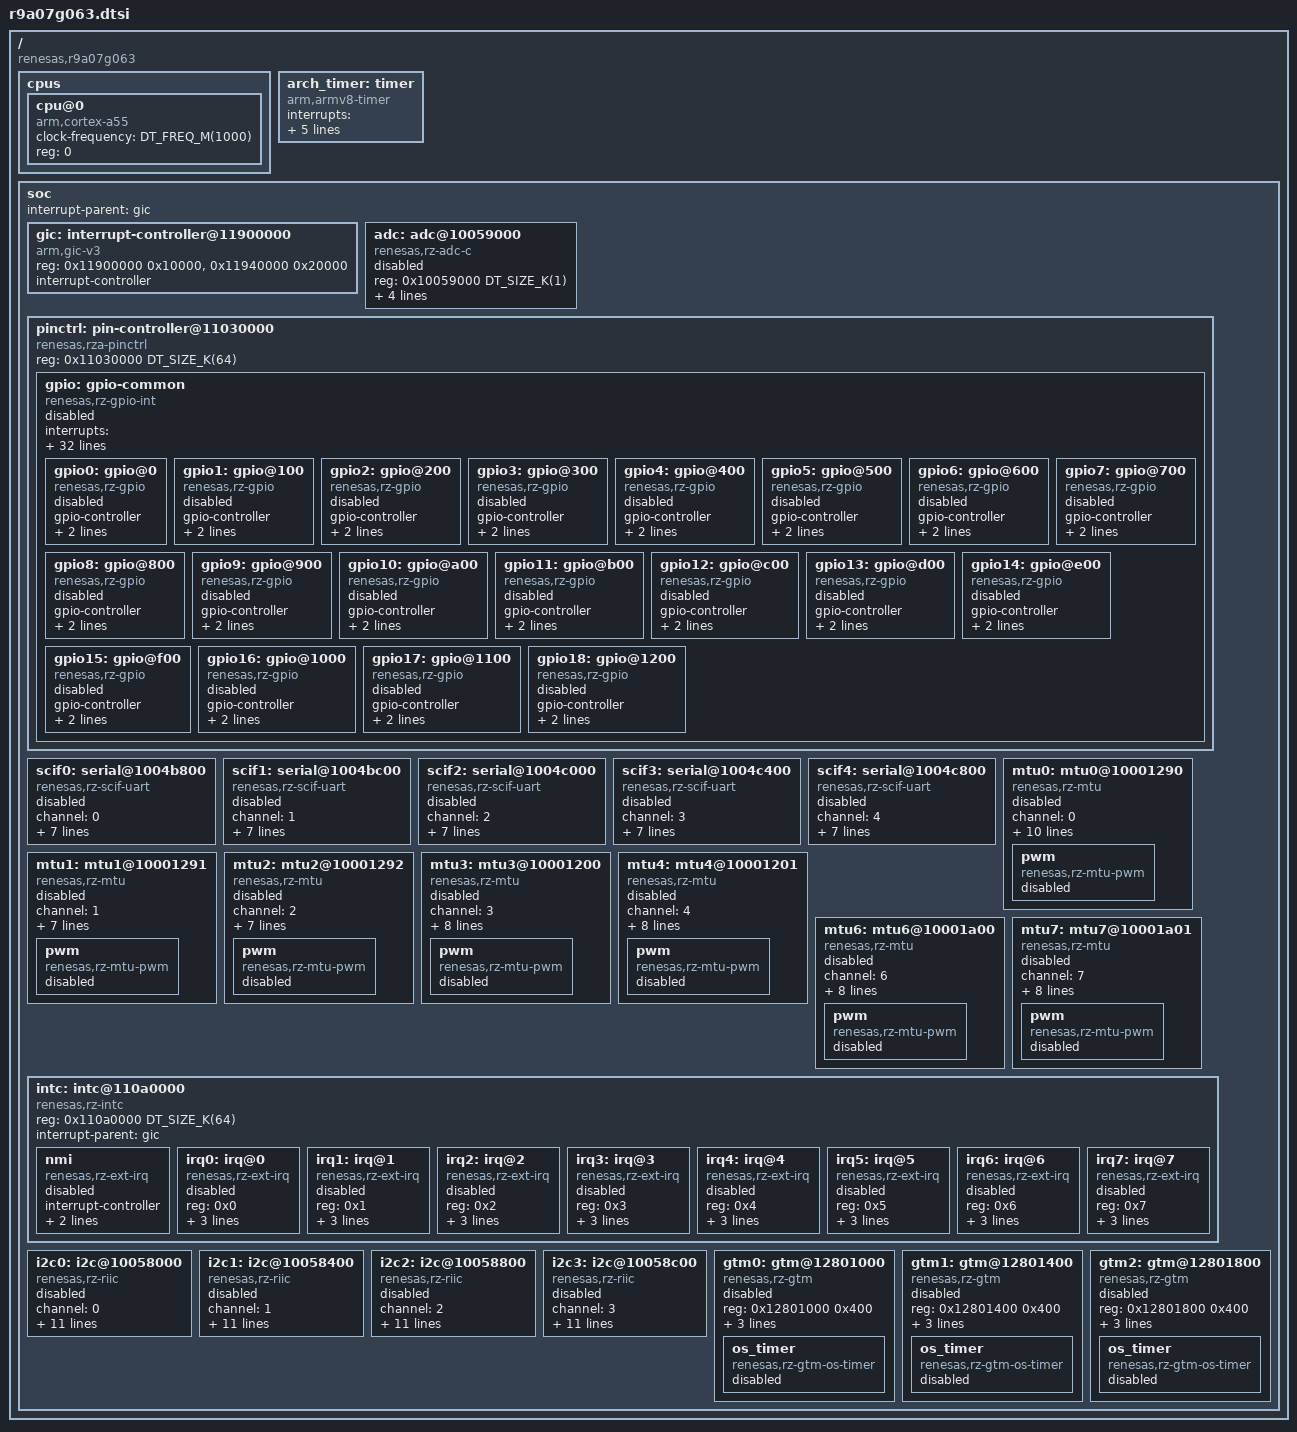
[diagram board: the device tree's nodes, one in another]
/*
 * Copyright (c) 2025 Renesas Electronics Corporation
 *
 * SPDX-License-Identifier: Apache-2.0
 */

#include <mem.h>
#include <freq.h>
#include <arm64/armv8-a.dtsi>
#include <zephyr/dt-bindings/interrupt-controller/arm-gic.h>
#include <zephyr/dt-bindings/gpio/gpio.h>
#include <zephyr/dt-bindings/pwm/renesas_rz_pwm.h>
#include <zephyr/dt-bindings/adc/adc.h>
#include <zephyr/dt-bindings/i2c/i2c.h>

/ {
	compatible = "renesas,r9a07g063";
	#address-cells = <1>;
	#size-cells = <1>;

	cpus {
		#address-cells = <1>;
		#size-cells = <0>;

		cpu@0 {
			device_type = "cpu";
			compatible = "arm,cortex-a55";
			clock-frequency = <DT_FREQ_M(1000)>;
			reg = <0>;
		};
	};

	arch_timer: timer {
		compatible = "arm,armv8-timer";
		interrupts = <GIC_PPI 13 IRQ_TYPE_LEVEL IRQ_DEFAULT_PRIORITY>,
			     <GIC_PPI 14 IRQ_TYPE_LEVEL IRQ_DEFAULT_PRIORITY>,
			     <GIC_PPI 11 IRQ_TYPE_LEVEL IRQ_DEFAULT_PRIORITY>,
			     <GIC_PPI 10 IRQ_TYPE_LEVEL IRQ_DEFAULT_PRIORITY>;
		interrupt-parent = <&gic>;
	};

	soc {
		interrupt-parent = <&gic>;

		gic: interrupt-controller@11900000 {
			compatible = "arm,gic-v3", "arm,gic";
			reg = <0x11900000 0x10000>, /* GICD */
			      <0x11940000 0x20000>; /* GICR */
			interrupt-controller;
			#interrupt-cells = <4>;
			status = "okay";
		};

		adc: adc@10059000 {
			compatible = "renesas,rz-adc-c";
			reg = <0x10059000 DT_SIZE_K(1)>;
			interrupts = <GIC_SPI 347 IRQ_TYPE_EDGE IRQ_DEFAULT_PRIORITY>;
			interrupt-names = "scanend";
			#io-channel-cells = <1>;
			vref-mv = <1800>;
			channel-available-mask = <0x3>;
			status = "disabled";
		};

		pinctrl: pin-controller@11030000 {
			compatible = "renesas,rza-pinctrl";
			reg = <0x11030000 DT_SIZE_K(64)>;
			reg-names = "pinctrl";

			gpio: gpio-common {
				compatible = "renesas,rz-gpio-int";
				interrupts = <GIC_SPI 444 IRQ_TYPE_LEVEL IRQ_DEFAULT_PRIORITY>,
					     <GIC_SPI 445 IRQ_TYPE_LEVEL IRQ_DEFAULT_PRIORITY>,
					     <GIC_SPI 446 IRQ_TYPE_LEVEL IRQ_DEFAULT_PRIORITY>,
					     <GIC_SPI 447 IRQ_TYPE_LEVEL IRQ_DEFAULT_PRIORITY>,
					     <GIC_SPI 448 IRQ_TYPE_LEVEL IRQ_DEFAULT_PRIORITY>,
					     <GIC_SPI 449 IRQ_TYPE_LEVEL IRQ_DEFAULT_PRIORITY>,
					     <GIC_SPI 450 IRQ_TYPE_LEVEL IRQ_DEFAULT_PRIORITY>,
					     <GIC_SPI 451 IRQ_TYPE_LEVEL IRQ_DEFAULT_PRIORITY>,
					     <GIC_SPI 452 IRQ_TYPE_LEVEL IRQ_DEFAULT_PRIORITY>,
					     <GIC_SPI 453 IRQ_TYPE_LEVEL IRQ_DEFAULT_PRIORITY>,
					     <GIC_SPI 454 IRQ_TYPE_LEVEL IRQ_DEFAULT_PRIORITY>,
					     <GIC_SPI 455 IRQ_TYPE_LEVEL IRQ_DEFAULT_PRIORITY>,
					     <GIC_SPI 456 IRQ_TYPE_LEVEL IRQ_DEFAULT_PRIORITY>,
					     <GIC_SPI 457 IRQ_TYPE_LEVEL IRQ_DEFAULT_PRIORITY>,
					     <GIC_SPI 458 IRQ_TYPE_LEVEL IRQ_DEFAULT_PRIORITY>,
					     <GIC_SPI 459 IRQ_TYPE_LEVEL IRQ_DEFAULT_PRIORITY>,
					     <GIC_SPI 460 IRQ_TYPE_LEVEL IRQ_DEFAULT_PRIORITY>,
					     <GIC_SPI 461 IRQ_TYPE_LEVEL IRQ_DEFAULT_PRIORITY>,
					     <GIC_SPI 462 IRQ_TYPE_LEVEL IRQ_DEFAULT_PRIORITY>,
					     <GIC_SPI 463 IRQ_TYPE_LEVEL IRQ_DEFAULT_PRIORITY>,
					     <GIC_SPI 464 IRQ_TYPE_LEVEL IRQ_DEFAULT_PRIORITY>,
					     <GIC_SPI 465 IRQ_TYPE_LEVEL IRQ_DEFAULT_PRIORITY>,
					     <GIC_SPI 466 IRQ_TYPE_LEVEL IRQ_DEFAULT_PRIORITY>,
					     <GIC_SPI 467 IRQ_TYPE_LEVEL IRQ_DEFAULT_PRIORITY>,
					     <GIC_SPI 468 IRQ_TYPE_LEVEL IRQ_DEFAULT_PRIORITY>,
					     <GIC_SPI 469 IRQ_TYPE_LEVEL IRQ_DEFAULT_PRIORITY>,
					     <GIC_SPI 470 IRQ_TYPE_LEVEL IRQ_DEFAULT_PRIORITY>,
					     <GIC_SPI 471 IRQ_TYPE_LEVEL IRQ_DEFAULT_PRIORITY>,
					     <GIC_SPI 472 IRQ_TYPE_LEVEL IRQ_DEFAULT_PRIORITY>,
					     <GIC_SPI 473 IRQ_TYPE_LEVEL IRQ_DEFAULT_PRIORITY>,
					     <GIC_SPI 474 IRQ_TYPE_LEVEL IRQ_DEFAULT_PRIORITY>,
					     <GIC_SPI 475 IRQ_TYPE_LEVEL IRQ_DEFAULT_PRIORITY>;
				#address-cells = <1>;
				#size-cells = <0>;
				status = "disabled";

				gpio0: gpio@0 {
					compatible = "renesas,rz-gpio";
					gpio-controller;
					#gpio-cells = <2>;
					ngpios = <4>;
					reg = <0x0>;
					status = "disabled";
				};

				gpio1: gpio@100 {
					compatible = "renesas,rz-gpio";
					gpio-controller;
					#gpio-cells = <2>;
					ngpios = <5>;
					reg = <0x100>;
					status = "disabled";
				};

				gpio2: gpio@200 {
					compatible = "renesas,rz-gpio";
					gpio-controller;
					#gpio-cells = <2>;
					ngpios = <4>;
					reg = <0x200>;
					status = "disabled";
				};

				gpio3: gpio@300 {
					compatible = "renesas,rz-gpio";
					gpio-controller;
					#gpio-cells = <2>;
					ngpios = <4>;
					reg = <0x300>;
					status = "disabled";
				};

				gpio4: gpio@400 {
					compatible = "renesas,rz-gpio";
					gpio-controller;
					#gpio-cells = <2>;
					ngpios = <6>;
					reg = <0x400>;
					status = "disabled";
				};

				gpio5: gpio@500 {
					compatible = "renesas,rz-gpio";
					gpio-controller;
					#gpio-cells = <2>;
					ngpios = <5>;
					reg = <0x500>;
					status = "disabled";
				};

				gpio6: gpio@600 {
					compatible = "renesas,rz-gpio";
					gpio-controller;
					#gpio-cells = <2>;
					ngpios = <5>;
					reg = <0x600>;
					status = "disabled";
				};

				gpio7: gpio@700 {
					compatible = "renesas,rz-gpio";
					gpio-controller;
					#gpio-cells = <2>;
					ngpios = <5>;
					reg = <0x700>;
					status = "disabled";
				};

				gpio8: gpio@800 {
					compatible = "renesas,rz-gpio";
					gpio-controller;
					#gpio-cells = <2>;
					ngpios = <5>;
					reg = <0x800>;
					status = "disabled";
				};

				gpio9: gpio@900 {
					compatible = "renesas,rz-gpio";
					gpio-controller;
					#gpio-cells = <2>;
					ngpios = <4>;
					reg = <0x900>;
					status = "disabled";
				};

				gpio10: gpio@a00 {
					compatible = "renesas,rz-gpio";
					gpio-controller;
					#gpio-cells = <2>;
					ngpios = <5>;
					reg = <0xa00>;
					status = "disabled";
				};

				gpio11: gpio@b00 {
					compatible = "renesas,rz-gpio";
					gpio-controller;
					#gpio-cells = <2>;
					ngpios = <4>;
					reg = <0xb00>;
					status = "disabled";
				};

				gpio12: gpio@c00 {
					compatible = "renesas,rz-gpio";
					gpio-controller;
					#gpio-cells = <2>;
					ngpios = <2>;
					reg = <0xc00>;
					status = "disabled";
				};

				gpio13: gpio@d00 {
					compatible = "renesas,rz-gpio";
					gpio-controller;
					#gpio-cells = <2>;
					ngpios = <5>;
					reg = <0xd00>;
					status = "disabled";
				};

				gpio14: gpio@e00 {
					compatible = "renesas,rz-gpio";
					gpio-controller;
					#gpio-cells = <2>;
					ngpios = <3>;
					reg = <0xe00>;
					status = "disabled";
				};

				gpio15: gpio@f00 {
					compatible = "renesas,rz-gpio";
					gpio-controller;
					#gpio-cells = <2>;
					ngpios = <4>;
					reg = <0xf00>;
					status = "disabled";
				};

				gpio16: gpio@1000 {
					compatible = "renesas,rz-gpio";
					gpio-controller;
					#gpio-cells = <2>;
					ngpios = <2>;
					reg = <0x1000>;
					status = "disabled";
				};

				gpio17: gpio@1100 {
					compatible = "renesas,rz-gpio";
					gpio-controller;
					#gpio-cells = <2>;
					ngpios = <4>;
					reg = <0x1100>;
					status = "disabled";
				};

				gpio18: gpio@1200 {
					compatible = "renesas,rz-gpio";
					gpio-controller;
					#gpio-cells = <2>;
					ngpios = <6>;
					reg = <0x1200>;
					status = "disabled";
				};
			};
		};

		scif0: serial@1004b800 {
			compatible = "renesas,rz-scif-uart";
			channel = <0>;
			reg = <0x1004b800 0x400>;
			interrupts = <GIC_SPI 380 IRQ_TYPE_LEVEL IRQ_DEFAULT_PRIORITY>,
				     <GIC_SPI 381 IRQ_TYPE_LEVEL IRQ_DEFAULT_PRIORITY>,
				     <GIC_SPI 382 IRQ_TYPE_LEVEL IRQ_DEFAULT_PRIORITY>,
				     <GIC_SPI 383 IRQ_TYPE_LEVEL IRQ_DEFAULT_PRIORITY>,
				     <GIC_SPI 384 IRQ_TYPE_LEVEL IRQ_DEFAULT_PRIORITY>;
			interrupt-names = "eri", "bri", "rxi", "txi", "tei";
			status = "disabled";
		};

		scif1: serial@1004bc00 {
			compatible = "renesas,rz-scif-uart";
			channel = <1>;
			reg = <0x1004bc00 0x400>;
			interrupts = <GIC_SPI 385 IRQ_TYPE_LEVEL IRQ_DEFAULT_PRIORITY>,
				     <GIC_SPI 386 IRQ_TYPE_LEVEL IRQ_DEFAULT_PRIORITY>,
				     <GIC_SPI 387 IRQ_TYPE_LEVEL IRQ_DEFAULT_PRIORITY>,
				     <GIC_SPI 388 IRQ_TYPE_LEVEL IRQ_DEFAULT_PRIORITY>,
				     <GIC_SPI 389 IRQ_TYPE_LEVEL IRQ_DEFAULT_PRIORITY>;
			interrupt-names = "eri", "bri", "rxi", "txi", "tei";
			status = "disabled";
		};

		scif2: serial@1004c000 {
			compatible = "renesas,rz-scif-uart";
			channel = <2>;
			reg = <0x1004c000 0x400>;
			interrupts = <GIC_SPI 390 IRQ_TYPE_LEVEL IRQ_DEFAULT_PRIORITY>,
				     <GIC_SPI 391 IRQ_TYPE_LEVEL IRQ_DEFAULT_PRIORITY>,
				     <GIC_SPI 392 IRQ_TYPE_LEVEL IRQ_DEFAULT_PRIORITY>,
				     <GIC_SPI 393 IRQ_TYPE_LEVEL IRQ_DEFAULT_PRIORITY>,
				     <GIC_SPI 394 IRQ_TYPE_LEVEL IRQ_DEFAULT_PRIORITY>;
			interrupt-names = "eri", "bri", "rxi", "txi", "tei";
			status = "disabled";
		};

		scif3: serial@1004c400 {
			compatible = "renesas,rz-scif-uart";
			channel = <3>;
			reg = <0x1004c400 0x400>;
			interrupts = <GIC_SPI 395 IRQ_TYPE_LEVEL IRQ_DEFAULT_PRIORITY>,
				     <GIC_SPI 396 IRQ_TYPE_LEVEL IRQ_DEFAULT_PRIORITY>,
				     <GIC_SPI 397 IRQ_TYPE_LEVEL IRQ_DEFAULT_PRIORITY>,
				     <GIC_SPI 399 IRQ_TYPE_LEVEL IRQ_DEFAULT_PRIORITY>,
				     <GIC_SPI 399 IRQ_TYPE_LEVEL IRQ_DEFAULT_PRIORITY>;
			interrupt-names = "eri", "bri", "rxi", "txi", "tei";
			status = "disabled";
		};

		scif4: serial@1004c800 {
			compatible = "renesas,rz-scif-uart";
			channel = <4>;
			reg = <0x1004c800 0x400>;
			interrupts = <GIC_SPI 400 IRQ_TYPE_LEVEL IRQ_DEFAULT_PRIORITY>,
				     <GIC_SPI 401 IRQ_TYPE_LEVEL IRQ_DEFAULT_PRIORITY>,
				     <GIC_SPI 402 IRQ_TYPE_LEVEL IRQ_DEFAULT_PRIORITY>,
				     <GIC_SPI 403 IRQ_TYPE_LEVEL IRQ_DEFAULT_PRIORITY>,
				     <GIC_SPI 404 IRQ_TYPE_LEVEL IRQ_DEFAULT_PRIORITY>;
			interrupt-names = "eri", "bri", "rxi", "txi", "tei";
			status = "disabled";
		};

		mtu0: mtu0@10001290 {
			compatible = "renesas,rz-mtu";
			channel = <0>;
			reg = <0x10001290 0x99>;
			interrupts = <GIC_SPI 170 IRQ_TYPE_EDGE IRQ_DEFAULT_PRIORITY>,
				     <GIC_SPI 171 IRQ_TYPE_EDGE IRQ_DEFAULT_PRIORITY>,
				     <GIC_SPI 172 IRQ_TYPE_EDGE IRQ_DEFAULT_PRIORITY>,
				     <GIC_SPI 173 IRQ_TYPE_EDGE IRQ_DEFAULT_PRIORITY>,
				     <GIC_SPI 174 IRQ_TYPE_EDGE IRQ_DEFAULT_PRIORITY>,
				     <GIC_SPI 175 IRQ_TYPE_EDGE IRQ_DEFAULT_PRIORITY>,
				     <GIC_SPI 176 IRQ_TYPE_EDGE IRQ_DEFAULT_PRIORITY>;
			interrupt-names = "tgia", "tgib", "tgic", "tgid", "tciv", "tgie", "tgif";
			prescaler = <1>;
			status = "disabled";

			pwm {
				compatible = "renesas,rz-mtu-pwm";
				#pwm-cells = <3>;
				status = "disabled";
			};
		};

		mtu1: mtu1@10001291 {
			compatible = "renesas,rz-mtu";
			channel = <1>;
			reg = <0x10001291 0x11b>;
			interrupts = <GIC_SPI 177 IRQ_TYPE_EDGE IRQ_DEFAULT_PRIORITY>,
				     <GIC_SPI 178 IRQ_TYPE_EDGE IRQ_DEFAULT_PRIORITY>,
				     <GIC_SPI 179 IRQ_TYPE_EDGE IRQ_DEFAULT_PRIORITY>,
				     <GIC_SPI 180 IRQ_TYPE_EDGE IRQ_DEFAULT_PRIORITY>;
			interrupt-names = "tgia", "tgib", "tciv", "tciu";
			prescaler = <1>;
			status = "disabled";

			pwm {
				compatible = "renesas,rz-mtu-pwm";
				#pwm-cells = <3>;
				status = "disabled";
			};
		};

		mtu2: mtu2@10001292 {
			compatible = "renesas,rz-mtu";
			channel = <2>;
			reg = <0x10001292 0x17b>;
			interrupts = <GIC_SPI 181 IRQ_TYPE_EDGE IRQ_DEFAULT_PRIORITY>,
				     <GIC_SPI 182 IRQ_TYPE_EDGE IRQ_DEFAULT_PRIORITY>,
				     <GIC_SPI 183 IRQ_TYPE_EDGE IRQ_DEFAULT_PRIORITY>,
				     <GIC_SPI 184 IRQ_TYPE_EDGE IRQ_DEFAULT_PRIORITY>;
			interrupt-names = "tgia", "tgib", "tciv", "tciu";
			prescaler = <1>;
			status = "disabled";

			pwm {
				compatible = "renesas,rz-mtu-pwm";
				#pwm-cells = <3>;
				status = "disabled";
			};
		};

		mtu3: mtu3@10001200 {
			compatible = "renesas,rz-mtu";
			channel = <3>;
			reg = <0x10001200 0x94>;
			interrupts = <GIC_SPI 185 IRQ_TYPE_EDGE IRQ_DEFAULT_PRIORITY>,
				     <GIC_SPI 186 IRQ_TYPE_EDGE IRQ_DEFAULT_PRIORITY>,
				     <GIC_SPI 187 IRQ_TYPE_EDGE IRQ_DEFAULT_PRIORITY>,
				     <GIC_SPI 188 IRQ_TYPE_EDGE IRQ_DEFAULT_PRIORITY>,
				     <GIC_SPI 189 IRQ_TYPE_EDGE IRQ_DEFAULT_PRIORITY>;
			interrupt-names = "tgia", "tgib", "tgic", "tgid", "tciv";
			prescaler = <1>;
			status = "disabled";

			pwm {
				compatible = "renesas,rz-mtu-pwm";
				#pwm-cells = <3>;
				status = "disabled";
			};
		};

		mtu4: mtu4@10001201 {
			compatible = "renesas,rz-mtu";
			channel = <4>;
			reg = <0x10001201 0x94>;
			interrupts = <GIC_SPI 190 IRQ_TYPE_EDGE IRQ_DEFAULT_PRIORITY>,
				     <GIC_SPI 191 IRQ_TYPE_EDGE IRQ_DEFAULT_PRIORITY>,
				     <GIC_SPI 192 IRQ_TYPE_EDGE IRQ_DEFAULT_PRIORITY>,
				     <GIC_SPI 193 IRQ_TYPE_EDGE IRQ_DEFAULT_PRIORITY>,
				     <GIC_SPI 194 IRQ_TYPE_EDGE IRQ_DEFAULT_PRIORITY>;
			interrupt-names = "tgia", "tgib", "tgic", "tgid", "tciv";
			prescaler = <1>;
			status = "disabled";

			pwm {
				compatible = "renesas,rz-mtu-pwm";
				#pwm-cells = <3>;
				status = "disabled";
			};
		};

		mtu6: mtu6@10001a00 {
			compatible = "renesas,rz-mtu";
			channel = <6>;
			reg = <0x10001a00 0x94>;
			interrupts = <GIC_SPI 198 IRQ_TYPE_EDGE IRQ_DEFAULT_PRIORITY>,
				     <GIC_SPI 199 IRQ_TYPE_EDGE IRQ_DEFAULT_PRIORITY>,
				     <GIC_SPI 200 IRQ_TYPE_EDGE IRQ_DEFAULT_PRIORITY>,
				     <GIC_SPI 201 IRQ_TYPE_EDGE IRQ_DEFAULT_PRIORITY>,
				     <GIC_SPI 202 IRQ_TYPE_EDGE IRQ_DEFAULT_PRIORITY>;
			interrupt-names = "tgia", "tgib", "tgic", "tgid", "tciv";
			prescaler = <1>;
			status = "disabled";

			pwm {
				compatible = "renesas,rz-mtu-pwm";
				#pwm-cells = <3>;
				status = "disabled";
			};
		};

		mtu7: mtu7@10001a01 {
			compatible = "renesas,rz-mtu";
			channel = <7>;
			reg = <0x10001a01 0x94>;
			interrupts = <GIC_SPI 203 IRQ_TYPE_EDGE IRQ_DEFAULT_PRIORITY>,
				     <GIC_SPI 204 IRQ_TYPE_EDGE IRQ_DEFAULT_PRIORITY>,
				     <GIC_SPI 205 IRQ_TYPE_EDGE IRQ_DEFAULT_PRIORITY>,
				     <GIC_SPI 206 IRQ_TYPE_EDGE IRQ_DEFAULT_PRIORITY>,
				     <GIC_SPI 207 IRQ_TYPE_EDGE IRQ_DEFAULT_PRIORITY>;
			interrupt-names = "tgia", "tgib", "tgic", "tgid", "tciv";
			prescaler = <1>;
			status = "disabled";

			pwm {
				compatible = "renesas,rz-mtu-pwm";
				#pwm-cells = <3>;
				status = "disabled";
			};
		};

		intc: intc@110a0000 {
			compatible = "renesas,rz-intc";
			reg = <0x110a0000 DT_SIZE_K(64)>;
			#address-cells = <1>;
			#size-cells = <0>;
			interrupt-parent = <&gic>;

			nmi: nmi {
				compatible = "renesas,rz-ext-irq";
				interrupt-controller;
				#interrupt-cells = <2>;
				interrupts = <GIC_SPI 0 IRQ_TYPE_LEVEL IRQ_DEFAULT_PRIORITY>;
				status = "disabled";
			};

			irq0: irq@0 {
				compatible = "renesas,rz-ext-irq";
				reg = <0x0>;
				interrupt-controller;
				#interrupt-cells = <2>;
				interrupts = <GIC_SPI 1 IRQ_TYPE_LEVEL IRQ_DEFAULT_PRIORITY>;
				status = "disabled";
			};

			irq1: irq@1 {
				compatible = "renesas,rz-ext-irq";
				reg = <0x1>;
				interrupt-controller;
				#interrupt-cells = <2>;
				interrupts = <GIC_SPI 2 IRQ_TYPE_LEVEL IRQ_DEFAULT_PRIORITY>;
				status = "disabled";
			};

			irq2: irq@2 {
				compatible = "renesas,rz-ext-irq";
				reg = <0x2>;
				interrupt-controller;
				#interrupt-cells = <2>;
				interrupts = <GIC_SPI 3 IRQ_TYPE_LEVEL IRQ_DEFAULT_PRIORITY>;
				status = "disabled";
			};

			irq3: irq@3 {
				compatible = "renesas,rz-ext-irq";
				reg = <0x3>;
				interrupt-controller;
				#interrupt-cells = <2>;
				interrupts = <GIC_SPI 4 IRQ_TYPE_LEVEL IRQ_DEFAULT_PRIORITY>;
				status = "disabled";
			};

			irq4: irq@4 {
				compatible = "renesas,rz-ext-irq";
				reg = <0x4>;
				interrupt-controller;
				#interrupt-cells = <2>;
				interrupts = <GIC_SPI 5 IRQ_TYPE_LEVEL IRQ_DEFAULT_PRIORITY>;
				status = "disabled";
			};

			irq5: irq@5 {
				compatible = "renesas,rz-ext-irq";
				reg = <0x5>;
				interrupt-controller;
				#interrupt-cells = <2>;
				interrupts = <GIC_SPI 6 IRQ_TYPE_LEVEL IRQ_DEFAULT_PRIORITY>;
				status = "disabled";
			};

			irq6: irq@6 {
				compatible = "renesas,rz-ext-irq";
				reg = <0x6>;
				interrupt-controller;
				#interrupt-cells = <2>;
				interrupts = <GIC_SPI 7 IRQ_TYPE_LEVEL IRQ_DEFAULT_PRIORITY>;
				status = "disabled";
			};

			irq7: irq@7 {
				compatible = "renesas,rz-ext-irq";
				reg = <0x7>;
				interrupt-controller;
				#interrupt-cells = <2>;
				interrupts = <GIC_SPI 8 IRQ_TYPE_LEVEL IRQ_DEFAULT_PRIORITY>;
				status = "disabled";
			};
		};

		i2c0: i2c@10058000 {
			compatible = "renesas,rz-riic";
			channel = <0>;
			clock-frequency = <I2C_BITRATE_STANDARD>;
			#address-cells = <1>;
			#size-cells = <0>;
			reg = <0x10058000 DT_SIZE_K(1)>;
			interrupts = <GIC_SPI 348 IRQ_TYPE_EDGE IRQ_DEFAULT_PRIORITY>,
				     <GIC_SPI 349 IRQ_TYPE_EDGE IRQ_DEFAULT_PRIORITY>,
				     <GIC_SPI 350 IRQ_TYPE_LEVEL IRQ_DEFAULT_PRIORITY>,
				     <GIC_SPI 351 IRQ_TYPE_LEVEL IRQ_DEFAULT_PRIORITY>,
				     <GIC_SPI 352 IRQ_TYPE_LEVEL IRQ_DEFAULT_PRIORITY>,
				     <GIC_SPI 353 IRQ_TYPE_LEVEL IRQ_DEFAULT_PRIORITY>,
				     <GIC_SPI 354 IRQ_TYPE_LEVEL IRQ_DEFAULT_PRIORITY>,
				     <GIC_SPI 355 IRQ_TYPE_LEVEL IRQ_DEFAULT_PRIORITY>;
			interrupt-names = "rxi", "txi", "tei", "naki", "spi", "sti", "ali", "tmoi";
			status = "disabled";
		};

		i2c1: i2c@10058400 {
			compatible = "renesas,rz-riic";
			channel = <1>;
			clock-frequency = <I2C_BITRATE_STANDARD>;
			#address-cells = <1>;
			#size-cells = <0>;
			reg = <0x10058400 DT_SIZE_K(1)>;
			interrupts = <GIC_SPI 356 IRQ_TYPE_EDGE IRQ_DEFAULT_PRIORITY>,
				     <GIC_SPI 357 IRQ_TYPE_EDGE IRQ_DEFAULT_PRIORITY>,
				     <GIC_SPI 358 IRQ_TYPE_LEVEL IRQ_DEFAULT_PRIORITY>,
				     <GIC_SPI 359 IRQ_TYPE_LEVEL IRQ_DEFAULT_PRIORITY>,
				     <GIC_SPI 360 IRQ_TYPE_LEVEL IRQ_DEFAULT_PRIORITY>,
				     <GIC_SPI 361 IRQ_TYPE_LEVEL IRQ_DEFAULT_PRIORITY>,
				     <GIC_SPI 362 IRQ_TYPE_LEVEL IRQ_DEFAULT_PRIORITY>,
				     <GIC_SPI 363 IRQ_TYPE_LEVEL IRQ_DEFAULT_PRIORITY>;
			interrupt-names = "rxi", "txi", "tei", "naki", "spi", "sti", "ali", "tmoi";
			status = "disabled";
		};

		i2c2: i2c@10058800 {
			compatible = "renesas,rz-riic";
			channel = <2>;
			clock-frequency = <I2C_BITRATE_STANDARD>;
			#address-cells = <1>;
			#size-cells = <0>;
			reg = <0x10058800 DT_SIZE_K(1)>;
			interrupts = <GIC_SPI 364 IRQ_TYPE_EDGE IRQ_DEFAULT_PRIORITY>,
				     <GIC_SPI 365 IRQ_TYPE_EDGE IRQ_DEFAULT_PRIORITY>,
				     <GIC_SPI 366 IRQ_TYPE_LEVEL IRQ_DEFAULT_PRIORITY>,
				     <GIC_SPI 367 IRQ_TYPE_LEVEL IRQ_DEFAULT_PRIORITY>,
				     <GIC_SPI 368 IRQ_TYPE_LEVEL IRQ_DEFAULT_PRIORITY>,
				     <GIC_SPI 369 IRQ_TYPE_LEVEL IRQ_DEFAULT_PRIORITY>,
				     <GIC_SPI 370 IRQ_TYPE_LEVEL IRQ_DEFAULT_PRIORITY>,
				     <GIC_SPI 371 IRQ_TYPE_LEVEL IRQ_DEFAULT_PRIORITY>;
			interrupt-names = "rxi", "txi", "tei", "naki", "spi", "sti", "ali", "tmoi";
			status = "disabled";
		};

		i2c3: i2c@10058c00 {
			compatible = "renesas,rz-riic";
			channel = <3>;
			clock-frequency = <I2C_BITRATE_STANDARD>;
			#address-cells = <1>;
			#size-cells = <0>;
			reg = <0x10058c00 DT_SIZE_K(1)>;
			interrupts = <GIC_SPI 372 IRQ_TYPE_EDGE IRQ_DEFAULT_PRIORITY>,
				     <GIC_SPI 373 IRQ_TYPE_EDGE IRQ_DEFAULT_PRIORITY>,
				     <GIC_SPI 374 IRQ_TYPE_LEVEL IRQ_DEFAULT_PRIORITY>,
				     <GIC_SPI 375 IRQ_TYPE_LEVEL IRQ_DEFAULT_PRIORITY>,
				     <GIC_SPI 376 IRQ_TYPE_LEVEL IRQ_DEFAULT_PRIORITY>,
				     <GIC_SPI 377 IRQ_TYPE_LEVEL IRQ_DEFAULT_PRIORITY>,
				     <GIC_SPI 378 IRQ_TYPE_LEVEL IRQ_DEFAULT_PRIORITY>,
				     <GIC_SPI 379 IRQ_TYPE_LEVEL IRQ_DEFAULT_PRIORITY>;
			interrupt-names = "rxi", "txi", "tei", "naki", "spi", "sti", "ali", "tmoi";
			status = "disabled";
		};

		gtm0: gtm@12801000 {
			compatible = "renesas,rz-gtm";
			reg = <0x12801000 0x400>;
			channel = <0>;
			interrupts = <GIC_SPI 46 IRQ_TYPE_EDGE IRQ_DEFAULT_PRIORITY>;
			interrupt-names = "overflow";
			status = "disabled";

			os_timer {
				compatible = "renesas,rz-gtm-os-timer";
				status = "disabled";
			};
		};

		gtm1: gtm@12801400 {
			compatible = "renesas,rz-gtm";
			reg = <0x12801400 0x400>;
			channel = <1>;
			interrupts = <GIC_SPI 47 IRQ_TYPE_EDGE IRQ_DEFAULT_PRIORITY>;
			interrupt-names = "overflow";
			status = "disabled";

			os_timer {
				compatible = "renesas,rz-gtm-os-timer";
				status = "disabled";
			};
		};

		gtm2: gtm@12801800 {
			compatible = "renesas,rz-gtm";
			reg = <0x12801800 0x400>;
			channel = <2>;
			interrupts = <GIC_SPI 48 IRQ_TYPE_EDGE IRQ_DEFAULT_PRIORITY>;
			interrupt-names = "overflow";
			status = "disabled";

			os_timer {
				compatible = "renesas,rz-gtm-os-timer";
				status = "disabled";
			};
		};
	};
};
